AUTOSAR XML (schema 4-2-1)
package /Component
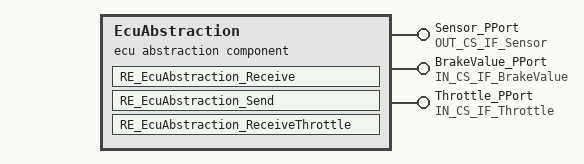
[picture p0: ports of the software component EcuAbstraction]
  ecu abstraction sw component type EcuAbstraction
    provide port Sensor_PPort: provided-interface=OUT_CS_IF_Sensor
    provide port BrakeValue_PPort: provided-interface=IN_CS_IF_BrakeValue
    provide port Throttle_PPort: provided-interface=IN_CS_IF_Throttle
    behavior IB_EcuAbstraction
      operation invoked event Send_EVENT: start-on-event=RE_EcuAbstraction_Send, operation=Sensor_PPort.ClientServerOperation_Sensor
      operation invoked event Brake_EVENT: start-on-event=RE_EcuAbstraction_Receive, operation=BrakeValue_PPort.ClientServerOperation_Brake
      operation invoked event Throttle_EVENT: start-on-event=RE_EcuAbstraction_ReceiveThrottle, operation=Throttle_PPort.ClientServerOperation_Throttle
      runnable RE_EcuAbstraction_Receive: symbol=RunnableEntity_EcuAbstraction_Receive_func
      runnable RE_EcuAbstraction_Send: symbol=RunnableEntity_WheelSpeed_func
      runnable RE_EcuAbstraction_ReceiveThrottle: symbol=RunnableEntity_Throttle_func
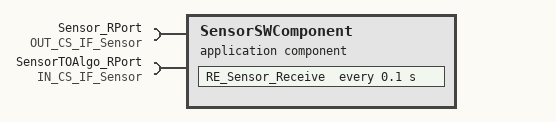
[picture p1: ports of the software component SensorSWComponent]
  application sw component type SensorSWComponent
    require port Sensor_RPort: required-interface=OUT_CS_IF_Sensor
    require port SensorTOAlgo_RPort: required-interface=IN_CS_IF_Sensor
    behavior IB_SensorSW
      timing event TimingEvent: start-on-event=RE_Sensor_Receive, period=0.1
      runnable RE_Sensor_Receive: symbol=RunnableEntity_WheelSpeedPlausi_Receive_func
        sync call Sensor_Syn_ServerCall: operation=Sensor_RPort.ClientServerOperation_Sensor
        sync call SensorToAlgo_Syn_ServerCall: operation=SensorTOAlgo_RPort.ClientServerOperation_Sensor
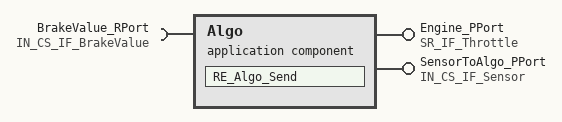
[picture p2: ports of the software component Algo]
  application sw component type Algo
    provide port Engine_PPort: provided-interface=SR_IF_Throttle
    provide port SensorToAlgo_PPort: provided-interface=IN_CS_IF_Sensor
    require port BrakeValue_RPort: required-interface=IN_CS_IF_BrakeValue
    behavior IB_Algo
      operation invoked event Sensor_EVENT: start-on-event=RE_Algo_Send, operation=SensorToAlgo_PPort.ClientServerOperation_Sensor
      runnable RE_Algo_Send: symbol=RunnableEntity_Send_func
        data-send-points:
          access SRA_SendPoint: accessed-variable=Engine_PPort.Throttle
        sync call Brake_Syn_ServerCall: operation=BrakeValue_RPort.ClientServerOperation_Brake
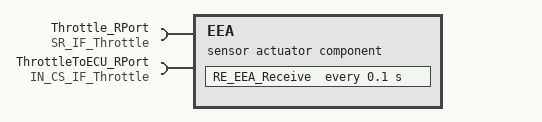
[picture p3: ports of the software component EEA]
  sensor actuator sw component type EEA
    require port Throttle_RPort: required-interface=SR_IF_Throttle
    require port ThrottleToECU_RPort: required-interface=IN_CS_IF_Throttle
    behavior IB_EEA
      timing event TimingEvent_Receive: start-on-event=RE_EEA_Receive, period=0.1
      runnable RE_EEA_Receive: symbol=RunnableEntity_EEA_Receive_func
        data-receive-point-by-arguments:
          access EEA_ReceiveByArgu: accessed-variable=Throttle_RPort.Throttle
        sync call ThrottleToECU_Syn_ServerCall: operation=ThrottleToECU_RPort.ClientServerOperation_Throttle
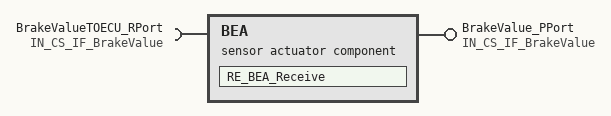
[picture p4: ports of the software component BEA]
  sensor actuator sw component type BEA
    provide port BrakeValue_PPort: provided-interface=IN_CS_IF_BrakeValue
    require port BrakeValueTOECU_RPort: required-interface=IN_CS_IF_BrakeValue
    behavior IB_BEA
      operation invoked event OperationInvokedEvent_BrakeValue: start-on-event=RE_BEA_Receive, operation=BrakeValue_PPort.ClientServerOperation_Brake
      runnable RE_BEA_Receive: symbol=RunnableEntity_BEA_Receive_func
        sync call BEA_Syn_ServerCall: operation=BrakeValueTOECU_RPort.ClientServerOperation_Brake
